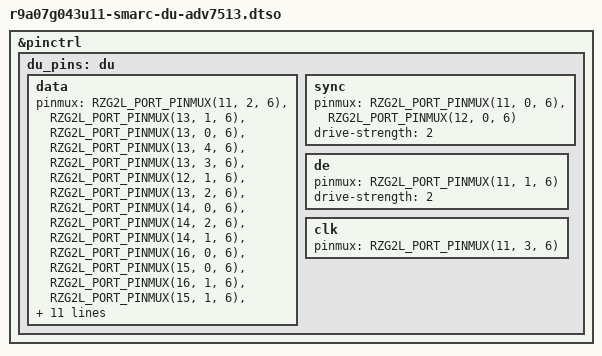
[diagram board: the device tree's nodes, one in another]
// SPDX-License-Identifier: GPL-2.0
/*
 * Device Tree overlay for the RZ/G2UL SMARC EVK with ADV7513 transmitter
 * connected to DU enabled.
 *
 * Copyright (C) 2024 Renesas Electronics Corp.
 */

/dts-v1/;
/plugin/;

#include <dt-bindings/pinctrl/rzg2l-pinctrl.h>

#define ADV7513_PARENT_I2C i2c1
#include "rz-smarc-du-adv7513.dtsi"

&pinctrl {
	du_pins: du {
		data {
			pinmux = <RZG2L_PORT_PINMUX(11, 2, 6)>,
				 <RZG2L_PORT_PINMUX(13, 1, 6)>,
				 <RZG2L_PORT_PINMUX(13, 0, 6)>,
				 <RZG2L_PORT_PINMUX(13, 4, 6)>,
				 <RZG2L_PORT_PINMUX(13, 3, 6)>,
				 <RZG2L_PORT_PINMUX(12, 1, 6)>,
				 <RZG2L_PORT_PINMUX(13, 2, 6)>,
				 <RZG2L_PORT_PINMUX(14, 0, 6)>,
				 <RZG2L_PORT_PINMUX(14, 2, 6)>,
				 <RZG2L_PORT_PINMUX(14, 1, 6)>,
				 <RZG2L_PORT_PINMUX(16, 0, 6)>,
				 <RZG2L_PORT_PINMUX(15, 0, 6)>,
				 <RZG2L_PORT_PINMUX(16, 1, 6)>,
				 <RZG2L_PORT_PINMUX(15, 1, 6)>,
				 <RZG2L_PORT_PINMUX(15, 3, 6)>,
				 <RZG2L_PORT_PINMUX(18, 0, 6)>,
				 <RZG2L_PORT_PINMUX(15, 2, 6)>,
				 <RZG2L_PORT_PINMUX(17, 0, 6)>,
				 <RZG2L_PORT_PINMUX(17, 2, 6)>,
				 <RZG2L_PORT_PINMUX(17, 1, 6)>,
				 <RZG2L_PORT_PINMUX(18, 1, 6)>,
				 <RZG2L_PORT_PINMUX(18, 2, 6)>,
				 <RZG2L_PORT_PINMUX(17, 3, 6)>,
				 <RZG2L_PORT_PINMUX(18, 3, 6)>;
			drive-strength = <2>;
		};

		sync {
			pinmux = <RZG2L_PORT_PINMUX(11, 0, 6)>, /* HSYNC */
				 <RZG2L_PORT_PINMUX(12, 0, 6)>; /* VSYNC */
			drive-strength = <2>;
		};

		de {
			pinmux = <RZG2L_PORT_PINMUX(11, 1, 6)>; /* DE */
			drive-strength = <2>;
		};

		clk {
			pinmux = <RZG2L_PORT_PINMUX(11, 3, 6)>; /* CLK */
		};
	};
};
